# CC3220SF register map
Vendor: Texas Instruments; Series: Wireless Connectivity MCU; File version: 1
CPU: CM4 r1p0, little endian, no MPU, no FPU, 8 interrupt priority bits
Registers are 32-bit, read-write, reset 0x0 unless marked. A register's access mark holds for its fields unless they carry their own. Offsets are from the block's base; [hi:lo] are bit positions; {n}, {i} and the like mark numbered series.

## OCP_SHARED
Base 0x4402E000
0x00 SEMAPHORE1
  [1:0] MEM_SEMAPHORE1 — General Purpose Semaphore for SW Usage. If any of the 2 bits of a given register is set to 1, it means that the semaphore is locked by one of the masters. Each bit represents a master IP as follows: {WLAN,NWP}. The JTAG cannot capture the semaphore but it can release it. As a master IP reads the semaphore, it will be caputed and the masters correlating bit will be set to 1 (set upon read). As any IP writes to this address (independent of the written data) the semaphore will be set to 2'b00.
0x04 SEMAPHORE2
  [1:0] MEM_SEMAPHORE2 — General Purpose Semaphore for SW Usage. If any of the 2 bits of a given register is set to 1, it means that the semaphore is locked by one of the masters. Each bit represents a master IP as follows: {WLAN,NWP}. The JTAG cannot capture the semaphore but it can release it. As a master IP reads the semaphore, it will be caputed and the masters correlating bit will be set to 1 (set upon read). As any IP writes to this address (independent of the written data) the semaphore will be set to 2'b00.
0x08 SEMAPHORE3
  [1:0] MEM_SEMAPHORE3 — General Purpose Semaphore for SW Usage. If any of the 2 bits of a given register is set to 1, it means that the semaphore is locked by one of the masters. Each bit represents a master IP as follows: {WLAN,NWP}. The JTAG cannot capture the semaphore but it can release it. As a master IP reads the semaphore, it will be caputed and the masters correlating bit will be set to 1 (set upon read). As any IP writes to this address (independent of the written data) the semaphore will be set to 2'b00.
0x0C SEMAPHORE4
  [1:0] MEM_SEMAPHORE4 — General Purpose Semaphore for SW Usage. If any of the 2 bits of a given register is set to 1, it means that the semaphore is locked by one of the masters. Each bit represents a master IP as follows: {WLAN,NWP}. The JTAG cannot capture the semaphore but it can release it. As a master IP reads the semaphore, it will be caputed and the masters correlating bit will be set to 1 (set upon read). As any IP writes to this address (independent of the written data) the semaphore will be set to 2'b00.
0x10 SEMAPHORE5
  [1:0] MEM_SEMAPHORE5 — General Purpose Semaphore for SW Usage. If any of the 2 bits of a given register is set to 1, it means that the semaphore is locked by one of the masters. Each bit represents a master IP as follows: {WLAN,NWP}. The JTAG cannot capture the semaphore but it can release it. As a master IP reads the semaphore, it will be caputed and the masters correlating bit will be set to 1 (set upon read). As any IP writes to this address (independent of the written data) the semaphore will be set to 2'b00.
0x14 SEMAPHORE6
  [1:0] MEM_SEMAPHORE6 — General Purpose Semaphore for SW Usage. If any of the 2 bits of a given register is set to 1, it means that the semaphore is locked by one of the masters. Each bit represents a master IP as follows: {WLAN,NWP}. The JTAG cannot capture the semaphore but it can release it. As a master IP reads the semaphore, it will be caputed and the masters correlating bit will be set to 1 (set upon read). As any IP writes to this address (independent of the written data) the semaphore will be set to 2'b00.
0x18 SEMAPHORE7
  [1:0] MEM_SEMAPHORE7 — General Purpose Semaphore for SW Usage. If any of the 2 bits of a given register is set to 1, it means that the semaphore is locked by one of the masters. Each bit represents a master IP as follows: {WLAN,NWP}. The JTAG cannot capture the semaphore but it can release it. As a master IP reads the semaphore, it will be caputed and the masters correlating bit will be set to 1 (set upon read). As any IP writes to this address (independent of the written data) the semaphore will be set to 2'b00.
0x1C SEMAPHORE8
  [1:0] MEM_SEMAPHORE8 — General Purpose Semaphore for SW Usage. If any of the 2 bits of a given register is set to 1, it means that the semaphore is locked by one of the masters. Each bit represents a master IP as follows: {WLAN,NWP}. The JTAG cannot capture the semaphore but it can release it. As a master IP reads the semaphore, it will be caputed and the masters correlating bit will be set to 1 (set upon read). As any IP writes to this address (independent of the written data) the semaphore will be set to 2'b00.
0x20 SEMAPHORE9
  [1:0] MEM_SEMAPHORE9 — General Purpose Semaphore for SW Usage. If any of the 2 bits of a given register is set to 1, it means that the semaphore is locked by one of the masters. Each bit represents a master IP as follows: {WLAN,NWP}. The JTAG cannot capture the semaphore but it can release it. As a master IP reads the semaphore, it will be caputed and the masters correlating bit will be set to 1 (set upon read). As any IP writes to this address (independent of the written data) the semaphore will be set to 2'b00.
0x24 SEMAPHORE10
  [1:0] MEM_SEMAPHORE10 — General Purpose Semaphore for SW Usage. If any of the 2 bits of a given register is set to 1, it means that the semaphore is locked by one of the masters. Each bit represents a master IP as follows: {WLAN,NWP}. The JTAG cannot capture the semaphore but it can release it. As a master IP reads the semaphore, it will be caputed and the masters correlating bit will be set to 1 (set upon read). As any IP writes to this address (independent of the written data) the semaphore will be set to 2'b00.
0x28 SEMAPHORE11
  [1:0] MEM_SEMAPHORE11 — General Purpose Semaphore for SW Usage. If any of the 2 bits of a given register is set to 1, it means that the semaphore is locked by one of the masters. Each bit represents a master IP as follows: {WLAN,NWP}. The JTAG cannot capture the semaphore but it can release it. As a master IP reads the semaphore, it will be caputed and the masters correlating bit will be set to 1 (set upon read). As any IP writes to this address (independent of the written data) the semaphore will be set to 2'b00.
0x2C SEMAPHORE12
  [1:0] MEM_SEMAPHORE12 — General Purpose Semaphore for SW Usage. If any of the 2 bits of a given register is set to 1, it means that the semaphore is locked by one of the masters. Each bit represents a master IP as follows: {WLAN,NWP}. The JTAG cannot capture the semaphore but it can release it. As a master IP reads the semaphore, it will be caputed and the masters correlating bit will be set to 1 (set upon read). As any IP writes to this address (independent of the written data) the semaphore will be set to 2'b00.
0x30 IC_LOCKER_ID
  [2:0] MEM_IC_LOCKER_ID — This register is used for allowing only one master OCP to perform write transactions to the OCP slaves. Each bit represents an IP in the following format: { JTAG,WLAN, NWP mcu}. As any of the bits is set to one, the correlating IP is preventing the other IP's from performing write transactions to the slaves. As the Inter Connect is locked, the only the locking IP can write to the register and by that releasing the lock. 3'b000 => IC is not locked. 3'b001 => IC is locked by NWP mcu. 3'b010 => IC is locked by WLAN. 3'b100 => IC is locked by JTAG.
0x34 MCU_SEMAPHORE_PEND
  [15:0] MEM_MCU_SEMAPHORE_PEND — This register specifies the semaphore for which the NWP mcu is waiting to be released. It is set to the serial number of a given locked semaphore after it was read by the NWP mcu. Only [11:0] is used.
0x38 WL_SEMAPHORE_PEND
  [15:0] MEM_WL_SEMAPHORE_PEND — This register specifies the semaphore for which the WLAN is waiting to be released. It is set to the serial number of a given locked semaphore after it was read by the WLAN. Only [11:0] is used.
0x3C PLATFORM_DETECTION_RD_ONLY
  [15:0] PLATFORM_DETECTION — This information serves the IPs for knowing in which platform are they integrated at: 0 = CC31XX.
0x40 SEMAPHORES_STATUS_RD_ONLY
  [11:0] SEMAPHORES_STATUS — Captured/released semaphores status for the 12 semaphores. Each bit of the 12 bits represents a semaphore. 0 => Semaphore Free. 1 => Semaphore Captured.
0x44 CC3XX_CONFIG_CTRL
0x48 CC3XX_SHARED_MEM_SEL_LSB
  [29:0] MEM_SHARED_MEM_SEL_LSB — This register provides memss RAM column configuration for column 0 to 9. 3 bits are allocated per column. This register is required to be configured before starting RAM access. Changing register setting while code is running will result into unpredictable memory behaviour. Register is supported to configured ones after core is booted up. 3 bit encoding per column is as follows: when 000 : WLAN, 001: NWP, 010: APPS, 011: PHY, 100: OCLA column 0 select: bit [2:0] :when 000 -> WLAN,001 -> NWP,010 -> APPS, 011 -> PHY, 100 -> OCLA column 1 select: bit [5:3] :column 2 select: bit [8 : 6]: column 3 select : bit [11: 9] column 4 select : bit [14:12] column 5 select : bit [17:15] column 6 select : bit [20:18] column 7 select : bit [23:21] column 8 select : bit [26:24] column 9 select : bit [29:27] column 10 select
0x4C CC3XX_SHARED_MEM_SEL_MSB
  [11:0] MEM_SHARED_MEM_SEL_MSB — This register provides memss RAM column configuration for column 10 to 15. 3 bits are allocated per column. This register is required to be configured before starting RAM access. Changing register setting while code is running will result into unpredictable memory behaviour. Register is supported to configured ones after core is booted up. 3 bit encoding per column is as follows: when 000 : WLAN, 001: NWP, 010: APPS, 011: PHY, 100: OCLA column 11 select : bit [2:0] column 12 select : bit [5:3] column 13 select : bit [8 : 6] column 14 select :
0x50 WLAN_ELP_WAKE_EN
0x54 DEVINIT_ROM_START_ADDR
0x58 DEVINIT_ROM_END_ADDR
0x5C SSBD_SEED
0x60 SSBD_CHK
0x64 SSBD_POLY_SEL
  [1:0] MEM_SSBD_POLY_SEL — 2 bit, Writable only during devinit, and whole 2 bit should be output of the config register module.
{0x68+4i} SPARE_REG_{i} (i=0..3)
0xA0 GPIO_PAD_CONFIG_0
  [11:0] MEM_GPIO_PAD_CONFIG_0 — GPIO 0 register: "Bit 0 - 3 is used for PAD IO mode selection. io_register={ "" 0 => """"CONFMODE[0]"""""" "" 1 => """"CONFMODE[1]"""""" "" 2 => """"CONFMODE[2]"""""" "" 3 => """"CONFMODE[3]"""" 4 => """"IODEN"""" --> When level 1 this disables the PMOS xtors of the output stages making them open-drain type." "For example in case of I2C Value gets latched at rising edge of RET33.""" """ 5 => """"I2MAEN"""" --> Level 1 enables the approx 2mA output stage""" """ 6 => """"I4MAEN"""" --> Level 1 enables the approx 4mA output stage""" """ 7 => """"I8MAEN"""" --> Level 1 enables the approx 8mA output stage. Note: any drive strength between 2mA and 14mA can be obtained with combination of 2mA 4mA and 8mA.""" """ 8 => """"IWKPUEN"""" --> 10uA pull up (weak strength)""" """ 9 => """"IWKPDEN"""" --> 10uA pull down (weak strength)""" """ 10 => """"IOE_N"""" --> output enable value. level 0 enables the IDO to PAD path. Else PAD is tristated (except for the PU/PD which are independent)." "Value gets latched at rising edge of RET33""" """ 11 =>"""" IOE_N_OV"""" --> output enable overirde. when bit is set to logic '1' IOE_N (bit 4) value will control IO IOE_N signal else IOE_N is control via selected HW logic. strong PULL UP and PULL Down control is disabled for all IO's. both controls are tied to logic level '0'.
{0xA0+4i} GPIO_PAD_CONFIG_{i} (i=1..32)
  [11:0] MEM_GPIO_PAD_CONFIG_{i} — GPIO 0 register: "Bit 0 - 3 is used for PAD IO mode selection. io_register={ "" 0 => """"CONFMODE[0]"""""" "" 1 => """"CONFMODE[1]"""""" "" 2 => """"CONFMODE[2]"""""" "" 3 => """"CONFMODE[3]"""" 4 => """"IODEN"""" --> When level 1 this disables the PMOS xtors of the output stages making them open-drain type." it can be used for I2C type of peripherals. 5 => """"I2MAEN"""" --> Level 1 enables the approx 2mA output stage""" """ 6 => """"I4MAEN"""" --> Level 1 enables the approx 4mA output stage""" """ 7 => """"I8MAEN"""" --> Level 1 enables the approx 8mA output stage. Note: any drive strength between 2mA and 14mA can be obtained with combination of 2mA 4mA and 8mA.""" """ 8 => """"IWKPUEN"""" --> 10uA pull up (weak strength)""" """ 9 => """"IWKPDEN"""" --> 10uA pull down (weak strength)""" """ 10 => """"IOE_N"""" --> output enable value. level 0 enables the IDO to PAD path. Else PAD is tristated (except for the PU/PD which are independent)." "Value gets latched at rising edge of RET33""" """ 11 =>"""" IOE_N_OV"""" --> output enable overirde. when bit is set to logic '1' IOE_N (bit 4) value will control IO IOE_N signal else IOE_N is control via selected HW logic. strong PULL UP and PULL Down control is disabled for all IO's. both controls are tied to logic level '0'.
{0xA0+4i} GPIO_PAD_CONFIG_{i} (i=33..39)
  [5:0] MEM_GPIO_PAD_CONFIG_{i} — GPIO 0 register: "Bit 0 - 3 is used for PAD IO mode selection. io_register={ "" 0 => """"CONFMODE[0]"""""" "" 1 => """"CONFMODE[1]"""""" "" 2 => """"CONFMODE[2]"""""" "" 3 => """"CONFMODE[3]"""" 4 => """"IOE_N"""" --> output enable value. level 0 enables the IDO to PAD path. Else PAD is tristated (except for the PU/PD which are independent)." "Value gets latched at rising edge of RET33""" """ 5 =>"""" IOE_N_OV"""" --> output enable overirde. when bit is set to logic '1' IOE_N (bit 4) value will control IO IOE_N signal else IOE_N is control via selected HW logic. strong PULL UP and PULL Down control is disabled for all IO's. both controls are tied to logic level '0'. IODEN and I8MAEN is diesabled for all development IO's. These signals are tied to logic level '0'. common control is implemented for I2MAEN, I4MAEN, WKPU, WKPD control . refer dev_pad_cmn_config register bits.
0x140 GPIO_PAD_CONFIG_40
  [18:0] MEM_GPIO_PAD_CONFIG_40 — GPIO 0 register: "Bit 0 - 3 is used for PAD IO mode selection. io_register={ "" 0 => """"CONFMODE[0]"""""" "" 1 => """"CONFMODE[1]"""""" "" 2 => """"CONFMODE[2]"""""" "" 3 => """"CONFMODE[3]"""" 4 => """"IODEN"""" --> When level 1 this disables the PMOS xtors of the output stages making them open-drain type." "For example in case of I2C Value gets latched at rising edge of RET33.""" """ 5 => """"I2MAEN"""" --> Level 1 enables the approx 2mA output stage""" """ 6 => """"I4MAEN"""" --> Level 1 enables the approx 4mA output stage""" """ 7 => """"I8MAEN"""" --> Level 1 enables the approx 8mA output stage. Note: any drive strength between 2mA and 14mA can be obtained with combination of 2mA 4mA and 8mA.""" """ 8 => """"IWKPUEN"""" --> 10uA pull up (weak strength)""" """ 9 => """"IWKPDEN"""" --> 10uA pull down (weak strength)""" """ 10 => """"IOE_N"""" --> output enable value. level 0 enables the IDO to PAD path. Else PAD is tristated (except for the PU/PD which are independent)." "Value gets latched at rising edge of RET33""" """ 11 =>"""" IOE_N_OV"""" --> output enable overirde. when bit is set to logic '1' IOE_N (bit 4) value will control IO IOE_N signal else IOE_N is control via selected HW logic. strong PULL UP and PULL Down control is disabled for all IO's. both controls are tied to logic level '0'.
0x144 GPIO_PAD_CMN_CONFIG — This register provide control to GPIO_CC3XXV1 IO PAD. Common control signals to all bottom Die IO's are controlled via this.
  [4:3] MEM_PAD_HYSTVAL — 00: hysteriris = 10% of VDDS (difference between upper and lower threshold of the schmit trigger) 01: hysteriris = 20% of VDDS (difference between upper and lower threshold of the schmit trigger) 10: hysteriris = 30% of VDDS (difference between upper and lower threshold of the schmit trigger) 11: hysteriris = 40% of VDDS (difference between upper and lower threshold of the schmit trigger)" """
0x148 D2D_DEV_PAD_CMN_CONFIG
  [5:0] MEM_DEV_PAD_CMN_CONF — this register implements common IO control to all devement mode PADs; these PADs are DEV_PAD33 to DEV_PAD39. Bit [1:0] : Drive strength control. These 2 bits are connected to DEV PAD drive strength control. possible drive stregnths are 2MA, 4MA and 6 MA for the these IO's. bit 0: when set to logic value '1' enable 2MA drive strength for DEVPAD01 to 07 bit 1: when set to logic value '1' enable 4MA drive strength for DEVPAD01 to 07. bit[3:2] : WK PULL UP and PULL down control. These 2 bits provide IWKPUEN and IWKPDEN control for all DEV IO's. bit 2: when set to logic value '1' enable WKPU to DEVPAD01 to 07 bit 3: when set to logic value '1' enable WKPD to DEVPAD01 to 07. bit 4: WK PULL control for DEV_PKG_DETECT pin. when '1' pullup enabled else it is disable. bit 5: when set to logic value '1' enable 8MA drive strength for DEVPAD01 to 07.
0x14C D2D_TOSTACK_PAD_CONF
  [28:0] MEM_D2D_TOSTACK_PAD_CONF — OEN/OEN2X control. When 0 : Act as input buffer else output buffer with drive strength 2. this register control OEN2X pin of D2D TOSTACK PAD: OEN1X and OEN2X decoding is as follows: "when ""00"" :" "when ""01"" : dirve strength is '1' and output buffer enabled." "when ""10"" : drive strength is 2 and output buffer is disabled." "when ""11"" : dirve strength is '3' and output buffer enabled."
0x150 D2D_MISC_PAD_CONF
  [2:0] MEM_D2D_SPARE — D2D SPARE PAD OEN/OEN2X control. When 0: Act as input buffer else output buffer with drive strength 2.
0x154 SOP_CONF_OVERRIDE
0x158 CC3XX_DEBUGSS_STATUS
0x15C CC3XX_DEBUGMUX_SEL
  [15:0] MEM_CC3XX_DEBUGMUX_SEL — debug mux select register. Upper 8 bits are used for debug module selection. Lower 8 bit [7:0] used inside debug module for selecting module specific signals. Bits[15:8: when set x"00" : GPRCM debug bus. When "o1" : SDIO debug debug bus when x"02" : autonoumous SPI when x"03" : TOPIC when x"04": memss when x"25": mcu debug bus : APPS debug when x"45": mcu debug bus : NWP debug when x"65": mcu debug bus : AHB2VBUS debug when x"85": mcu debug bus : VBUS2HAB debug when x"95": mcu debug bus : RCM debug when x"A5": mcu debug bus : crypto debug when x"06": WLAN debug bus when x"07": debugss bus when x"08": ADC debug when x"09": SDIO PHY debug bus then "others" : no debug is selected
0x160 ALT_PC_VAL_NW
0x164 ALT_PC_VAL_APPS
0x168 SPARE_REG_4
  [31:1] MEM_SPARE_REG_4 — HW register
0x16C SPARE_REG_5
0x170 SH_SPI_CS_MASK
  [3:0] MEM_SH_SPI_CS_MASK — ( chip select 0 is unmasked after reset. When 1 : CS is unmasked or else masked. Valid configurations are 1000, 0100, 0010 or 0001. Any other setting can lead to unpredictable behavior.
0x174 CC3XX_DEVICE_TYPE
  [4:0] DEVICE_TYPE — CC3XX Device type information.
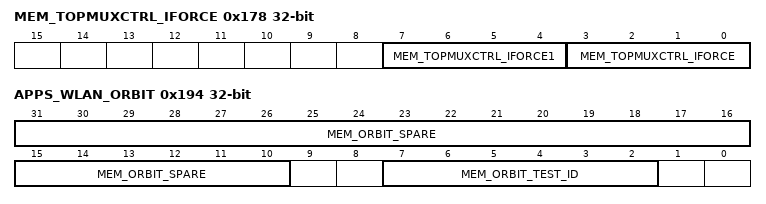
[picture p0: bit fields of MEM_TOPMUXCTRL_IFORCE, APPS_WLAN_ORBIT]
0x178 MEM_TOPMUXCTRL_IFORCE
  [7:4] MEM_TOPMUXCTRL_IFORCE1 — [4] 1: switch between WLAN_I2C_SCL and TOP_GPIO_PORT4_I2C closes 0: switch opens [5] 1: switch between WLAN_I2C_SCL and TOP_VSENSE_PORT closes 0: switch opens [6] 1: switch between WLAN_I2C_SCL and WLAN_ANA_TP4 closes 0: switch opens [7] Reserved
  [3:0] MEM_TOPMUXCTRL_IFORCE — [0] 1: switch between WLAN_I2C_SDA and TOP_GPIO_PORT3_I2C closes 0: switch opens [1] 1: switch between WLAN_I2C_SDA and TOP_IFORCE_PORT closes 0: switch opens [2] 1: switch between WLAN_I2C_SDA and WLAN_ANA_TP3 closes 0: switch opens [3] Reserved
0x17C CC3XX_DEV_PACKAGE_DETECT
0x180 AUTONMS_SPICLK_SEL
0x184 CC3XX_DEV_PADCONF
  [15:0] MEM_CC3XX_DEV_PADCONF
0x188 SPARE_REG_8
0x18C SPARE_REG_6
0x190 SPARE_REG_7
0x194 APPS_WLAN_ORBIT
  [31:10] MEM_ORBIT_SPARE — Spare bit
  [7:2] MEM_ORBIT_TEST_ID — Implies the test case ID that needs to run.
0x198 APPS_WLAN_SCRATCH_PAD
